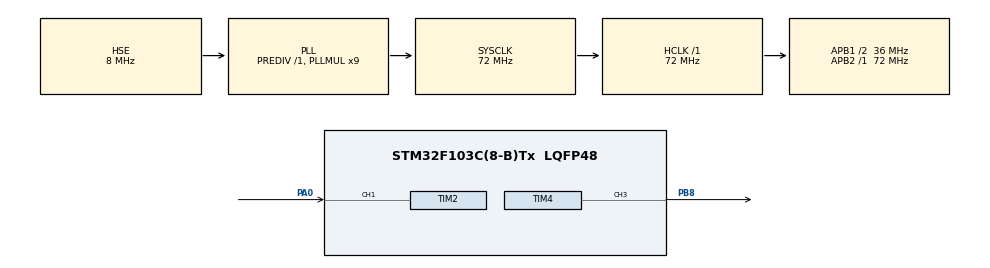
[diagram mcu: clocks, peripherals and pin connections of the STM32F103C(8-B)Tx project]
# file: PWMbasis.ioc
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Mcu.Family=STM32F1
Mcu.Name=STM32F103C(8-B)Tx
Mcu.Package=LQFP48
NVIC.PriorityGroup=NVIC_PRIORITYGROUP_4
NVIC.TIM2_IRQn=true\:0\:0\:false\:false\:true\:true\:true\:true
PA0-WKUP.Signal=S_TIM2_CH1_ETR
PA13.Mode=Serial_Wire
PA13.Signal=SYS_JTMS-SWDIO
PA14.Mode=Serial_Wire
PA14.Signal=SYS_JTCK-SWCLK
PB8.Signal=S_TIM4_CH3
PD0-OSC_IN.Mode=HSE-External-Oscillator
PD0-OSC_IN.Signal=RCC_OSC_IN
PD1-OSC_OUT.Mode=HSE-External-Oscillator
PD1-OSC_OUT.Signal=RCC_OSC_OUT
ProjectManager.HeapSize=0x200
ProjectManager.StackSize=0x400
ProjectManager.TargetToolchain=STM32CubeIDE
RCC.AHBFreq_Value=72000000
RCC.APB1CLKDivider=RCC_HCLK_DIV2
RCC.APB1Freq_Value=36000000
RCC.APB1TimFreq_Value=72000000
RCC.APB2Freq_Value=72000000
RCC.APB2TimFreq_Value=72000000
RCC.HCLKFreq_Value=72000000
RCC.PLLMUL=RCC_PLL_MUL9
RCC.PLLSourceVirtual=RCC_PLLSOURCE_HSE
RCC.SYSCLKFreq_VALUE=72000000
RCC.SYSCLKSource=RCC_SYSCLKSOURCE_PLLCLK
RCC.USBFreq_Value=72000000
SH.S_TIM2_CH1_ETR.0=TIM2_CH1,TriggerSource_TI1FP1
SH.S_TIM2_CH1_ETR.1=TIM2_CH1,Input_Capture1_from_TI1
SH.S_TIM4_CH3.0=TIM4_CH3,PWM Generation3 CH3
TIM2.Channel-Input_Capture1_from_TI1=TIM_CHANNEL_1
TIM2.Channel-Input_Capture2_from_TI1_63=TIM_CHANNEL_2
TIM2.ICPolarity_CH1=TIM_INPUTCHANNELPOLARITY_FALLING
TIM2.Prescaler=359
TIM4.Channel-PWM\ Generation3\ CH3=TIM_CHANNEL_3
TIM4.OCMode_PWM-PWM\ Generation3\ CH3=TIM_OCMODE_PWM2
TIM4.Prescaler=359
VP_TIM2_VS_ClockSourceINT.Mode=Internal
VP_TIM2_VS_ControllerModeReset.Mode=Reset Mode
VP_TIM2_VS_indirect_ch1.Mode=Input_Capture2_from_TI1_63
board=custom

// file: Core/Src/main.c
/* USER CODE BEGIN Header */
/**
  ******************************************************************************
  * @file           : main.c
  * @brief          : Main program body
  ******************************************************************************
  * @attention
  *
  * Copyright (c) 2023 STMicroelectronics.
  * All rights reserved.
  *
  * This software is licensed under terms that can be found in the LICENSE file
  * in the root directory of this software component.
  * If no LICENSE file comes with this software, it is provided AS-IS.
  *
  ******************************************************************************
  */
/* USER CODE END Header */
#include "main.h"

/* USER CODE BEGIN PTD */
typedef struct
{
	uint16_t frequency;
	uint16_t duty;
}CAP_Tim_Var_type;
/* USER CODE END PTD */

TIM_HandleTypeDef htim2;
TIM_HandleTypeDef htim4;

/* USER CODE BEGIN PV */
CAP_Tim_Var_type CAP_TIM_VAR;
uint16_t duty;
uint16_t frequency;
/* USER CODE END PV */

void SystemClock_Config(void);
static void MX_GPIO_Init(void);
static void MX_TIM4_Init(void);
static void MX_TIM2_Init(void);
/* USER CODE BEGIN PFP */
uint16_t CAP_ReadFrequency(void)
{
	uint16_t frequency = 0;

	frequency = CAP_TIM_VAR.frequency;
	CAP_TIM_VAR.frequency = 0;

	return(frequency);

}

uint16_t CAP_ReadDuty(void)
{
	uint16_t duty = 0;

	duty = CAP_TIM_VAR.duty;
	CAP_TIM_VAR.duty = 0;

	return(duty);

}
/* USER CODE END PFP */

int main(void)
{

  /* MCU Configuration--------------------------------------------------------*/

  /* Reset of all peripherals, Initializes the Flash interface and the Systick. */
  HAL_Init();

  /* Configure the system clock */
  SystemClock_Config();

  /* Initialize all configured peripherals */
  MX_GPIO_Init();
  MX_TIM4_Init();
  MX_TIM2_Init();
  /* USER CODE BEGIN 2 */
  HAL_TIM_PWM_Start(&htim4, TIM_CHANNEL_3); //start timer 4 channel 3
  __HAL_TIM_SET_AUTORELOAD(&htim4, 2000);//start PWM frequency 50Hz (36MHz/360 = 1KHz /2000)
  __HAL_TIM_SET_COMPARE(&htim4, TIM_CHANNEL_3, 600); // Set 30% from ARR (2000) --> 10% Duty cycle

  HAL_Delay(100);

  HAL_TIM_IC_Start_IT(&htim2, TIM_CHANNEL_1);
  HAL_TIM_IC_Start(&htim2, TIM_CHANNEL_2);

  /* USER CODE END 2 */

  /* Infinite loop */
  while (1)
  {

    /* USER CODE BEGIN 3 */

	  HAL_Delay(50);
	  frequency = CAP_ReadFrequency();
	  duty = CAP_ReadDuty();

  }
  /* USER CODE END 3 */
}

void SystemClock_Config(void)
{
  RCC_OscInitTypeDef RCC_OscInitStruct = {0};
  RCC_ClkInitTypeDef RCC_ClkInitStruct = {0};

  /** Initializes the RCC Oscillators according to the specified parameters
  * in the RCC_OscInitTypeDef structure.
  */
  RCC_OscInitStruct.OscillatorType = RCC_OSCILLATORTYPE_HSE;
  RCC_OscInitStruct.HSEState = RCC_HSE_ON;
  RCC_OscInitStruct.HSEPredivValue = RCC_HSE_PREDIV_DIV1;
  RCC_OscInitStruct.HSIState = RCC_HSI_ON;
  RCC_OscInitStruct.PLL.PLLState = RCC_PLL_ON;
  RCC_OscInitStruct.PLL.PLLSource = RCC_PLLSOURCE_HSE;
  RCC_OscInitStruct.PLL.PLLMUL = RCC_PLL_MUL9;
  if (HAL_RCC_OscConfig(&RCC_OscInitStruct) != HAL_OK)
  {
    Error_Handler();
  }

  /** Initializes the CPU, AHB and APB buses clocks
  */
  RCC_ClkInitStruct.ClockType = RCC_CLOCKTYPE_HCLK|RCC_CLOCKTYPE_SYSCLK
                              |RCC_CLOCKTYPE_PCLK1|RCC_CLOCKTYPE_PCLK2;
  RCC_ClkInitStruct.SYSCLKSource = RCC_SYSCLKSOURCE_PLLCLK;
  RCC_ClkInitStruct.AHBCLKDivider = RCC_SYSCLK_DIV1;
  RCC_ClkInitStruct.APB1CLKDivider = RCC_HCLK_DIV2;
  RCC_ClkInitStruct.APB2CLKDivider = RCC_HCLK_DIV1;

  if (HAL_RCC_ClockConfig(&RCC_ClkInitStruct, FLASH_LATENCY_2) != HAL_OK)
  {
    Error_Handler();
  }
}

static void MX_TIM2_Init(void)
{

  TIM_ClockConfigTypeDef sClockSourceConfig = {0};
  TIM_SlaveConfigTypeDef sSlaveConfig = {0};
  TIM_MasterConfigTypeDef sMasterConfig = {0};
  TIM_IC_InitTypeDef sConfigIC = {0};

  htim2.Instance = TIM2;
  htim2.Init.Prescaler = 359;
  htim2.Init.CounterMode = TIM_COUNTERMODE_UP;
  htim2.Init.Period = 65535;
  htim2.Init.ClockDivision = TIM_CLOCKDIVISION_DIV1;
  htim2.Init.AutoReloadPreload = TIM_AUTORELOAD_PRELOAD_DISABLE;
  if (HAL_TIM_Base_Init(&htim2) != HAL_OK)
  {
    Error_Handler();
  }
  sClockSourceConfig.ClockSource = TIM_CLOCKSOURCE_INTERNAL;
  if (HAL_TIM_ConfigClockSource(&htim2, &sClockSourceConfig) != HAL_OK)
  {
    Error_Handler();
  }
  if (HAL_TIM_IC_Init(&htim2) != HAL_OK)
  {
    Error_Handler();
  }
  sSlaveConfig.SlaveMode = TIM_SLAVEMODE_RESET;
  sSlaveConfig.InputTrigger = TIM_TS_TI1FP1;
  sSlaveConfig.TriggerPolarity = TIM_INPUTCHANNELPOLARITY_FALLING;
  sSlaveConfig.TriggerFilter = 0;
  if (HAL_TIM_SlaveConfigSynchro(&htim2, &sSlaveConfig) != HAL_OK)
  {
    Error_Handler();
  }
  sMasterConfig.MasterOutputTrigger = TIM_TRGO_RESET;
  sMasterConfig.MasterSlaveMode = TIM_MASTERSLAVEMODE_DISABLE;
  if (HAL_TIMEx_MasterConfigSynchronization(&htim2, &sMasterConfig) != HAL_OK)
  {
    Error_Handler();
  }
  sConfigIC.ICPolarity = TIM_INPUTCHANNELPOLARITY_FALLING;
  sConfigIC.ICSelection = TIM_ICSELECTION_DIRECTTI;
  sConfigIC.ICPrescaler = TIM_ICPSC_DIV1;
  sConfigIC.ICFilter = 0;
  if (HAL_TIM_IC_ConfigChannel(&htim2, &sConfigIC, TIM_CHANNEL_1) != HAL_OK)
  {
    Error_Handler();
  }
  sConfigIC.ICPolarity = TIM_INPUTCHANNELPOLARITY_RISING;
  sConfigIC.ICSelection = TIM_ICSELECTION_INDIRECTTI;
  if (HAL_TIM_IC_ConfigChannel(&htim2, &sConfigIC, TIM_CHANNEL_2) != HAL_OK)
  {
    Error_Handler();
  }

}

static void MX_TIM4_Init(void)
{

  TIM_MasterConfigTypeDef sMasterConfig = {0};
  TIM_OC_InitTypeDef sConfigOC = {0};

  htim4.Instance = TIM4;
  htim4.Init.Prescaler = 359;
  htim4.Init.CounterMode = TIM_COUNTERMODE_UP;
  htim4.Init.Period = 65535;
  htim4.Init.ClockDivision = TIM_CLOCKDIVISION_DIV1;
  htim4.Init.AutoReloadPreload = TIM_AUTORELOAD_PRELOAD_DISABLE;
  if (HAL_TIM_PWM_Init(&htim4) != HAL_OK)
  {
    Error_Handler();
  }
  sMasterConfig.MasterOutputTrigger = TIM_TRGO_RESET;
  sMasterConfig.MasterSlaveMode = TIM_MASTERSLAVEMODE_DISABLE;
  if (HAL_TIMEx_MasterConfigSynchronization(&htim4, &sMasterConfig) != HAL_OK)
  {
    Error_Handler();
  }
  sConfigOC.OCMode = TIM_OCMODE_PWM2;
  sConfigOC.Pulse = 0;
  sConfigOC.OCPolarity = TIM_OCPOLARITY_HIGH;
  sConfigOC.OCFastMode = TIM_OCFAST_DISABLE;
  if (HAL_TIM_PWM_ConfigChannel(&htim4, &sConfigOC, TIM_CHANNEL_3) != HAL_OK)
  {
    Error_Handler();
  }
  HAL_TIM_MspPostInit(&htim4);

}

static void MX_GPIO_Init(void)
{

  /* GPIO Ports Clock Enable */
  __HAL_RCC_GPIOD_CLK_ENABLE();
  __HAL_RCC_GPIOA_CLK_ENABLE();
  __HAL_RCC_GPIOB_CLK_ENABLE();

}

/* USER CODE BEGIN 4 */
//Imput ca[ture callback function
void HAL_TIM_IC_CaptureCallback(TIM_HandleTypeDef *htim)
{
	if(htim->Instance == TIM2)
	{
		CAP_TIM_VAR.frequency = __HAL_TIM_GET_COMPARE(&htim2, TIM_CHANNEL_1);
		CAP_TIM_VAR.duty =  __HAL_TIM_GET_COMPARE(&htim2, TIM_CHANNEL_2);
	}
}
/* USER CODE END 4 */

void Error_Handler(void)
{
  __disable_irq();
  while (1)
  {
  }
}
